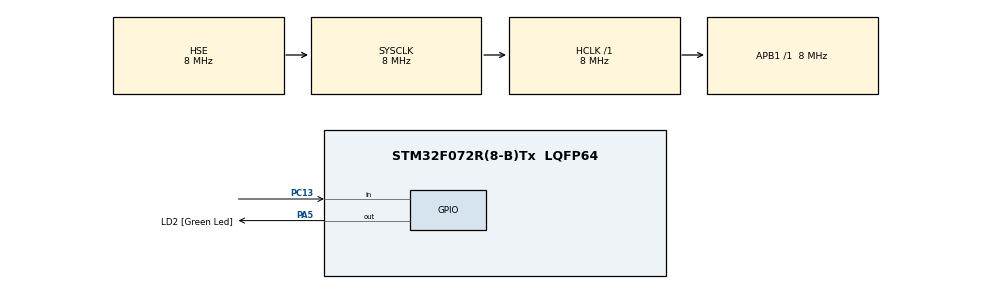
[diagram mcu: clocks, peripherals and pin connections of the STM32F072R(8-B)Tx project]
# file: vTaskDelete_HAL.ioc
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FREERTOS.Tasks01=Task1,0,128,Task1Handler,Default,NULL,Dynamic,NULL,NULL;Task2,1,128,Task2Handler,Default,NULL,Dynamic,NULL,NULL
Mcu.Family=STM32F0
Mcu.Name=STM32F072R(8-B)Tx
Mcu.Package=LQFP64
PA13.GPIO_Label=TMS
PA13.Mode=Serial_Wire
PA13.Signal=SYS_SWDIO
PA14.GPIO_Label=TCK
PA14.Mode=Serial_Wire
PA14.Signal=SYS_SWCLK
PA5.GPIO_Label=LD2 [Green Led]
PA5.GPIO_Mode=GPIO_MODE_OUTPUT_PP
PA5.GPIO_PuPd=GPIO_NOPULL
PA5.GPIO_Speed=GPIO_SPEED_FREQ_LOW
PA5.Signal=GPIO_Output
PC13.GPIO_PuPd=GPIO_PULLDOWN
PC13.Signal=GPIO_Input
PC14-OSC32_IN.Signal=RCC_OSC32_IN
PC15-OSC32_OUT.Signal=RCC_OSC32_OUT
PF0-OSC_IN.Mode=HSE-External-Oscillator
PF0-OSC_IN.Signal=RCC_OSC_IN
PF1-OSC_OUT.Mode=HSE-External-Oscillator
PF1-OSC_OUT.Signal=RCC_OSC_OUT
ProjectManager.HeapSize=0x200
ProjectManager.StackSize=0x400
ProjectManager.TargetToolchain=STM32CubeIDE
RCC.AHBFreq_Value=8000000
RCC.APB1Freq_Value=8000000
RCC.APB1TimFreq_Value=8000000
RCC.FLatency-AdvancedSettings=FLASH_LATENCY_0
RCC.HCLKFreq_Value=8000000
RCC.PLLDivider=RCC_PREDIV_DIV2
RCC.PLLMUL=RCC_PLL_MUL12
RCC.PREFETCH_ENABLE-AdvancedSettings=1
RCC.SYSCLKFreq_VALUE=8000000
RCC.SYSCLKSource=RCC_SYSCLKSOURCE_HSE
VP_FREERTOS_VS_CMSIS_V1.Mode=CMSIS_V1
board=NUCLEO-F072RB

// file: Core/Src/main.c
/* USER CODE BEGIN Header */
/**
  ******************************************************************************
  * @file           : main.c
  * @brief          : Main program body
  ******************************************************************************
  * @attention
  *
  * Copyright (c) 2024 STMicroelectronics.
  * All rights reserved.
  *
  * This software is licensed under terms that can be found in the LICENSE file
  * in the root directory of this software component.
  * If no LICENSE file comes with this software, it is provided AS-IS.
  *
  ******************************************************************************
  */
/* USER CODE END Header */
#include "main.h"
#include "cmsis_os.h"

/* USER CODE BEGIN PD */
uint32_t count=0;
GPIO_PinState buttonState = 0 ;
/* USER CODE END PD */

osThreadId Task1Handle;
osThreadId Task2Handle;

void SystemClock_Config(void);
static void MX_GPIO_Init(void);
void Task1Handler(void const * argument);
void Task2Handler(void const * argument);

int main(void)
{

  /* MCU Configuration--------------------------------------------------------*/

  /* Reset of all peripherals, Initializes the Flash interface and the Systick. */
  HAL_Init();

  /* Configure the system clock */
  SystemClock_Config();

  /* Initialize all configured peripherals */
  MX_GPIO_Init();

  /* Create the thread(s) */
  /* definition and creation of Task1 */
  osThreadDef(Task1, Task1Handler, osPriorityNormal, 0, 128);
  Task1Handle = osThreadCreate(osThread(Task1), NULL);

  /* definition and creation of Task2 */
  osThreadDef(Task2, Task2Handler, osPriorityAboveNormal, 0, 128);
  Task2Handle = osThreadCreate(osThread(Task2), NULL);

  /* Start scheduler */
  osKernelStart();
  /* We should never get here as control is now taken by the scheduler */
  /* Infinite loop */
  while (1)
  {

  }
}

void SystemClock_Config(void)
{
  RCC_OscInitTypeDef RCC_OscInitStruct = {0};
  RCC_ClkInitTypeDef RCC_ClkInitStruct = {0};

  /** Initializes the RCC Oscillators according to the specified parameters
  * in the RCC_OscInitTypeDef structure.
  */
  RCC_OscInitStruct.OscillatorType = RCC_OSCILLATORTYPE_HSE;
  RCC_OscInitStruct.HSEState = RCC_HSE_ON;
  RCC_OscInitStruct.PLL.PLLState = RCC_PLL_NONE;
  if (HAL_RCC_OscConfig(&RCC_OscInitStruct) != HAL_OK)
  {
    Error_Handler();
  }

  /** Initializes the CPU, AHB and APB buses clocks
  */
  RCC_ClkInitStruct.ClockType = RCC_CLOCKTYPE_HCLK|RCC_CLOCKTYPE_SYSCLK
                              |RCC_CLOCKTYPE_PCLK1;
  RCC_ClkInitStruct.SYSCLKSource = RCC_SYSCLKSOURCE_HSE;
  RCC_ClkInitStruct.AHBCLKDivider = RCC_SYSCLK_DIV1;
  RCC_ClkInitStruct.APB1CLKDivider = RCC_HCLK_DIV1;

  if (HAL_RCC_ClockConfig(&RCC_ClkInitStruct, FLASH_LATENCY_0) != HAL_OK)
  {
    Error_Handler();
  }
}

static void MX_GPIO_Init(void)
{
  GPIO_InitTypeDef GPIO_InitStruct = {0};

  /* GPIO Ports Clock Enable */
  __HAL_RCC_GPIOC_CLK_ENABLE();
  __HAL_RCC_GPIOF_CLK_ENABLE();
  __HAL_RCC_GPIOA_CLK_ENABLE();

  /*Configure GPIO pin Output Level */
  HAL_GPIO_WritePin(LD2_GPIO_Port, LD2_Pin, GPIO_PIN_RESET);

  /*Configure GPIO pin : PC13 */
  GPIO_InitStruct.Pin = GPIO_PIN_13;
  GPIO_InitStruct.Mode = GPIO_MODE_INPUT;
  GPIO_InitStruct.Pull = GPIO_PULLDOWN;
  HAL_GPIO_Init(GPIOC, &GPIO_InitStruct);

  /*Configure GPIO pin : LD2_Pin */
  GPIO_InitStruct.Pin = LD2_Pin;
  GPIO_InitStruct.Mode = GPIO_MODE_OUTPUT_PP;
  GPIO_InitStruct.Pull = GPIO_NOPULL;
  GPIO_InitStruct.Speed = GPIO_SPEED_FREQ_LOW;
  HAL_GPIO_Init(LD2_GPIO_Port, &GPIO_InitStruct);

}

void Task1Handler(void const * argument)
{
  /* USER CODE BEGIN 5 */
  /* Infinite loop */
  for(;;)
  {

	  HAL_GPIO_TogglePin(GPIOA, GPIO_PIN_5);
	  HAL_Delay(500);

	  //osDelay(1); // vTaskDelay(); ile aynı şeyler
  }
  /* USER CODE END 5 */
}

void Task2Handler(void const * argument)
{
  /* USER CODE BEGIN Task2Handler */
  /* Infinite loop */
  for(;;)
  {
	  HAL_GPIO_TogglePin(GPIOA, GPIO_PIN_5);
	  HAL_Delay(2000);
	 buttonState = HAL_GPIO_ReadPin(GPIOC, GPIO_PIN_13);
	  	  if(buttonState==GPIO_PIN_SET)
	  	  {
	  		 // while(HAL_GPIO_ReadPin(GPIOC, GPIO_PIN_13)==1);
	  		  count++;
	  		  osThreadSuspend(Task2Handle); // görevi askıya alan bir fonksiyon gibi düşün
	  		  //vTaskDelete ile aynı işi yapar
	  	  }

    //osDelay(1);
  }
  /* USER CODE END Task2Handler */
}

void Error_Handler(void)
{
  __disable_irq();
  while (1)
  {
  }
}
